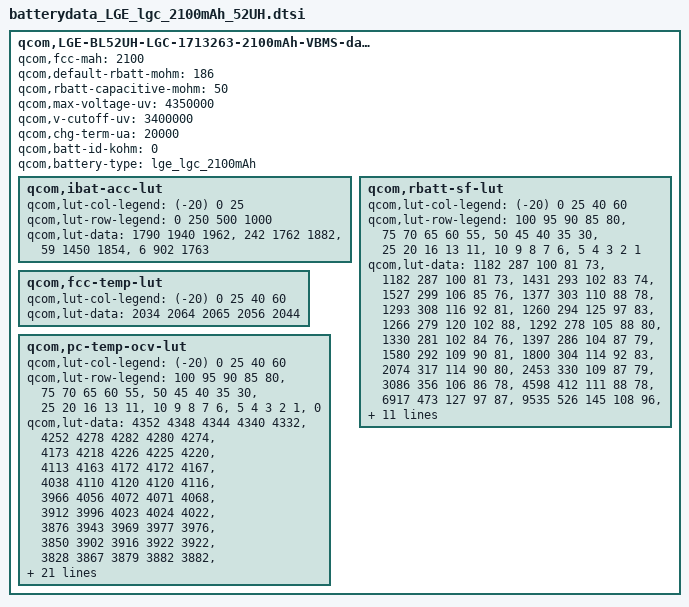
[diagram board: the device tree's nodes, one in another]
 qcom,LGE-BL52UH-LGC-1713263-2100mAh-VBMS-data {
	qcom,fcc-mah = <2100>;
	qcom,default-rbatt-mohm = <186>;
	qcom,rbatt-capacitive-mohm = <50>;
	qcom,max-voltage-uv = <4350000>;
	qcom,v-cutoff-uv = <3400000>;
	qcom,chg-term-ua = <20000>;
	qcom,batt-id-kohm = <0>;
    qcom,battery-type = "lge_lgc_2100mAh";

	qcom,ibat-acc-lut {
		qcom,lut-col-legend = <(-20) 0 25>;
		qcom,lut-row-legend = <0 250 500 1000>;
		qcom,lut-data = <1790 1940 1962>,
				<242 1762 1882>,
				<59 1450 1854>,
				<6 902 1763>;
	};

	qcom,rbatt-sf-lut {
		qcom,lut-col-legend = <(-20) 0 25 40 60>;
		qcom,lut-row-legend = <100 95 90 85 80>,
				<75 70 65 60 55>,
				<50 45 40 35 30>,
				<25 20 16 13 11>,
				<10 9 8 7 6>,
				<5 4 3 2 1>;
		qcom,lut-data = <1182 287 100 81 73>,
				<1182 287 100 81 73>,
				<1431 293 102 83 74>,
				<1527 299 106 85 76>,
				<1377 303 110 88 78>,
				<1293 308 116 92 81>,
				<1260 294 125 97 83>,
				<1266 279 120 102 88>,
				<1292 278 105 88 80>,
				<1330 281 102 84 76>,
				<1397 286 104 87 79>,
				<1580 292 109 90 81>,
				<1800 304 114 92 83>,
				<2074 317 114 90 80>,
				<2453 330 109 87 79>,
				<3086 356 106 86 78>,
				<4598 412 111 88 78>,
				<6917 473 127 97 87>,
				<9535 526 145 108 96>,
				<11816 564 158 115 100>,
				<12988 586 165 118 102>,
				<14300 574 167 121 105>,
				<15531 564 174 127 110>,
				<16225 604 188 135 116>,
				<18644 660 208 146 121>,
				<21858 744 232 158 128>,
				<26278 993 259 172 138>,
				<31509 1527 298 192 152>,
				<37210 2365 383 233 178>,
				<44131 4198 609 346 252>;
	};

	qcom,fcc-temp-lut {
		qcom,lut-col-legend = <(-20) 0 25 40 60>;
		qcom,lut-data = <2034 2064 2065 2056 2044>;
	};

	qcom,pc-temp-ocv-lut {
		qcom,lut-col-legend = <(-20) 0 25 40 60>;
		qcom,lut-row-legend = <100 95 90 85 80>,
				<75 70 65 60 55>,
				<50 45 40 35 30>,
				<25 20 16 13 11>,
				<10 9 8 7 6>,
				<5 4 3 2 1>,
				<0>;
		qcom,lut-data = <4352 4348 4344 4340 4332>,
				<4252 4278 4282 4280 4274>,
				<4173 4218 4226 4225 4220>,
				<4113 4163 4172 4172 4167>,
				<4038 4110 4120 4120 4116>,
				<3966 4056 4072 4071 4068>,
				<3912 3996 4023 4024 4022>,
				<3876 3943 3969 3977 3976>,
				<3850 3902 3916 3922 3922>,
				<3828 3867 3879 3882 3882>,
				<3805 3836 3850 3852 3852>,
				<3782 3808 3825 3827 3827>,
				<3757 3786 3804 3803 3802>,
				<3728 3766 3780 3777 3770>,
				<3692 3741 3751 3747 3738>,
				<3639 3716 3709 3706 3698>,
				<3554 3693 3688 3682 3671>,
				<3472 3663 3668 3664 3654>,
				<3414 3613 3632 3632 3624>,
				<3376 3564 3592 3596 3586>,
				<3356 3537 3567 3572 3562>,
				<3331 3508 3538 3544 3535>,
				<3306 3474 3506 3512 3504>,
				<3276 3440 3474 3480 3472>,
				<3250 3406 3441 3448 3440>,
				<3226 3372 3407 3414 3407>,
				<3210 3334 3367 3374 3367>,
				<3186 3286 3316 3323 3315>,
				<3150 3230 3251 3254 3244>,
				<3102 3150 3161 3155 3150>,
				<3000 3000 3000 3000 3000>;
	};
};
